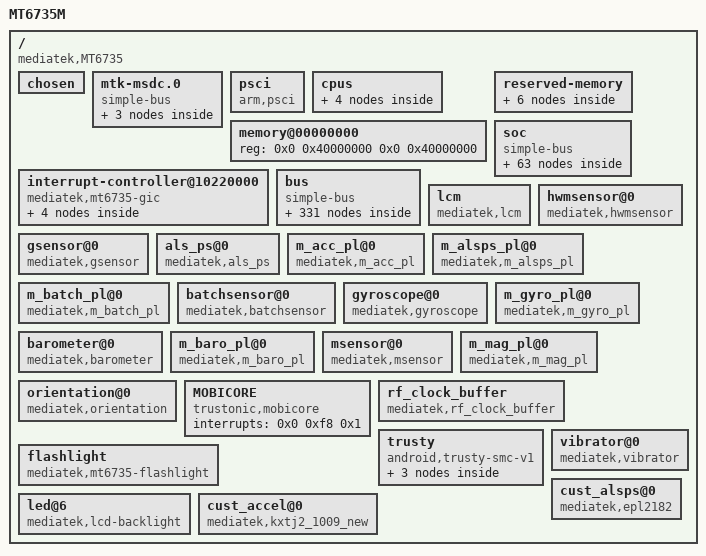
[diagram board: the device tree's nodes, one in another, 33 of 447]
/dts-v1/;

/ {
	model = "MT6735M";
	compatible = "mediatek,MT6735";
	interrupt-parent = <0x1>;
	#address-cells = <0x2>;
	#size-cells = <0x2>;

	chosen {
		bootargs = "console=tty0 console=ttyMT0,921600n1 root=/dev/ram \t\t\tinitrd=0x44000000,0x1000000 loglevel=8 androidboot.hardware=mt6735";
	};

	mtk-msdc.0 {
		compatible = "simple-bus";
		#address-cells = <0x1>;
		#size-cells = <0x1>;
		ranges = <0x0 0x0 0x0 0xffffffff>;

		msdc0@11230000 {
			compatible = "mediatek,mt6735m-mmc";
			reg = <0x11230000 0x10000 0x10000e84 0x2>;
			interrupts = <0x0 0x4f 0x8>;
			status = "okay";
			clk_src = [02];
			bus-width = <0x8>;
			max-frequency = <0xbebc200>;
			cap-mmc-highspeed;
			msdc-sys-suspend;
			mmc-ddr-1_8v;
			mmc-hs200-1_8v;
			mmc-hs400-1_8v;
			non-removable;
			pinctl = <0x2>;
			register_setting = <0x3>;
			host_function = [00];
			bootable;
		};

		msdc1@11240000 {
			compatible = "mediatek,mt6735m-mmc";
			reg = <0x11240000 0x10000 0x10000e84 0x2>;
			interrupts = <0x0 0x50 0x8>;
			status = "okay";
			clk_src = [02];
			bus-width = <0x4>;
			max-frequency = <0xbebc200>;
			msdc-sys-suspend;
			cap-sd-highspeed;
			sd-uhs-sdr12;
			sd-uhs-sdr25;
			sd-uhs-sdr50;
			sd-uhs-sdr104;
			sd-uhs-ddr50;
			pinctl = <0x4>;
			pinctl_sdr104 = <0x5>;
			pinctl_sdr50 = <0x6>;
			pinctl_ddr50 = <0x7>;
			register_setting = <0x8>;
			host_function = [01];
			cd_level = [00];
			cd-gpios = <0x9 0x5 0x0>;
		};

		default {
			compatible = "mediatek, msdc1_ins-eint";
			interrupt-parent = <0xa>;
			interrupts = <0x5 0x8>;
			debounce = <0x5 0x3e8>;
			status = "okay";
		};
	};

	psci {
		compatible = "arm,psci";
		method = "smc";
		cpu_suspend = <0x84000001>;
		cpu_off = <0x84000002>;
		cpu_on = <0x84000003>;
		affinity_info = <0x84000004>;
	};

	cpus {
		#address-cells = <0x1>;
		#size-cells = <0x0>;

		cpu@000 {
			device_type = "cpu";
			compatible = "arm,cortex-a53";
			reg = <0x0>;
			enable-method = "spin-table";
			cpu-release-addr = <0x0 0x40000200>;
			clock-frequency = <0x3b9aca00>;
			linux,phandle = <0xb>;
			phandle = <0xb>;
		};

		cpu@001 {
			device_type = "cpu";
			compatible = "arm,cortex-a53";
			reg = <0x1>;
			enable-method = "spin-table";
			cpu-release-addr = <0x0 0x40000200>;
			clock-frequency = <0x3b9aca00>;
			linux,phandle = <0xc>;
			phandle = <0xc>;
		};

		cpu@002 {
			device_type = "cpu";
			compatible = "arm,cortex-a53";
			reg = <0x2>;
			enable-method = "spin-table";
			cpu-release-addr = <0x0 0x40000200>;
			clock-frequency = <0x3b9aca00>;
			linux,phandle = <0xd>;
			phandle = <0xd>;
		};

		cpu@003 {
			device_type = "cpu";
			compatible = "arm,cortex-a53";
			reg = <0x3>;
			enable-method = "spin-table";
			cpu-release-addr = <0x0 0x40000200>;
			clock-frequency = <0x3b9aca00>;
			linux,phandle = <0xe>;
			phandle = <0xe>;
		};
	};

	memory@00000000 {
		device_type = "memory";
		reg = <0x0 0x40000000 0x0 0x40000000>;
	};

	reserved-memory {
		#address-cells = <0x2>;
		#size-cells = <0x2>;
		ranges;

		atf-reserved-memory@43000000 {
			compatible = "mediatek,mt6735-atf-reserved-memory", "mediatek,mt6735m-atf-reserved-memory", "mediatek,mt6753-atf-reserved-memory";
			no-map;
			reg = <0x0 0x43000000 0x0 0x30000>;
		};

		reserve-memory-ccci_md1 {
			compatible = "mediatek,reserve-memory-ccci_md1";
			no-map;
			size = <0x0 0x3810000>;
			alignment = <0x0 0x2000000>;
			alloc-ranges = <0x0 0x40000000 0x0 0xc0000000>;
		};

		consys-reserve-memory {
			compatible = "mediatek,consys-reserve-memory";
			no-map;
			size = <0x0 0x100000>;
			alignment = <0x0 0x200000>;
		};

		ram_console-reserved-memory@43f00000 {
			compatible = "mediatek,ram_console";
			reg = <0x0 0x43f00000 0x0 0x10000>;
		};

		minirdump-reserved-memory@43ff0000 {
			compatible = "mediatek, minirdump";
			reg = <0x0 0x43ff0000 0x0 0x10000>;
		};

		pstore-reserved-memory@43f10000 {
			compatible = "mediatek,pstore";
			reg = <0x0 0x43f10000 0x0 0xe0000>;
		};
	};

	interrupt-controller@10220000 {
		compatible = "mediatek,mt6735-gic";
		#interrupt-cells = <0x3>;
		#address-cells = <0x0>;
		interrupt-controller;
		reg = <0x0 0x10221000 0x0 0x1000 0x0 0x10222000 0x0 0x1000 0x0 0x10200620 0x0 0x1000>;
		mediatek,wdt_irq = <0xa0>;
		linux,phandle = <0x1>;
		phandle = <0x1>;

		gic-cpuif@0 {
			compatible = "arm,gic-cpuif";
			cpuif-id = <0x0>;
			cpu = <0xb>;
		};

		gic-cpuif@1 {
			compatible = "arm,gic-cpuif";
			cpuif-id = <0x1>;
			cpu = <0xc>;
		};

		gic-cpuif@2 {
			compatible = "arm,gic-cpuif";
			cpuif-id = <0x2>;
			cpu = <0xd>;
		};

		gic-cpuif@3 {
			compatible = "arm,gic-cpuif";
			cpuif-id = <0x3>;
			cpu = <0xe>;
		};
	};

	soc {
		compatible = "simple-bus";
		#address-cells = <0x1>;
		#size-cells = <0x1>;
		ranges;

		cpuxgpt@10200000 {
			compatible = "mediatek,mt6735-cpuxgpt";
			reg = <0x10200000 0x1000>;
			interrupts = <0x0 0x40 0x4 0x0 0x41 0x4 0x0 0x42 0x4 0x0 0x43 0x4 0x0 0x44 0x4 0x0 0x45 0x4 0x0 0x46 0x4 0x0 0x47 0x4>;
		};

		apxgpt@10004000 {
			compatible = "mediatek,mt6735-apxgpt";
			reg = <0x10004000 0x1000>;
			interrupts = <0x0 0x98 0x8>;
			clock-frequency = <0xc65d40>;
		};

		timer {
			compatible = "arm,armv8-timer";
			interrupts = <0x1 0xd 0x8 0x1 0xe 0x8 0x1 0xb 0x8 0x1 0xa 0x8>;
			clock-frequency = <0xc65d40>;
		};

		mt_pmic_regulator {
			compatible = "mediatek,mt_pmic";

			buck_regulators {
				compatible = "mediatek,mt_pmic_buck_regulators";

				buck_vpa {
					regulator-name = "vpa";
					regulator-min-microvolt = <0x7a120>;
					regulator-max-microvolt = <0x37b1d0>;
					regulator-ramp-delay = <0xc350>;
					regulator-enable-ramp-delay = <0xb4>;
				};

				buck_vproc {
					regulator-name = "vproc";
					regulator-min-microvolt = <0x927c0>;
					regulator-max-microvolt = <0x154456>;
					regulator-ramp-delay = <0x186a>;
					regulator-enable-ramp-delay = <0xb4>;
					regulator-always-on;
					regulator-boot-on;
				};

				buck_vcore1 {
					regulator-name = "vcore1";
					regulator-min-microvolt = <0x927c0>;
					regulator-max-microvolt = <0x154456>;
					regulator-ramp-delay = <0x186a>;
					regulator-enable-ramp-delay = <0xb4>;
					regulator-always-on;
					regulator-boot-on;
				};

				buck_vsys22 {
					regulator-name = "vsys22";
					regulator-min-microvolt = <0x124f80>;
					regulator-max-microvolt = <0x1e6c16>;
					regulator-ramp-delay = <0x186a>;
					regulator-enable-ramp-delay = <0xb4>;
					regulator-always-on;
					regulator-boot-on;
				};

				buck_vlte {
					regulator-name = "vlte";
					regulator-min-microvolt = <0x927c0>;
					regulator-max-microvolt = <0x154456>;
					regulator-ramp-delay = <0x186a>;
					regulator-enable-ramp-delay = <0xb4>;
					regulator-always-on;
					regulator-boot-on;
				};
			};

			ldo_regulators {
				compatible = "mediatek,mt_pmic_ldo_regulators";

				ldo_vaux18 {
					regulator-name = "vaux18";
					regulator-min-microvolt = <0x1b7740>;
					regulator-max-microvolt = <0x1b7740>;
					regulator-enable-ramp-delay = <0x108>;
					regulator-boot-on;
					linux,phandle = <0xf>;
					phandle = <0xf>;
				};

				ldo_vtcxo_0 {
					regulator-name = "vtcxo_0";
					regulator-min-microvolt = <0x2ab980>;
					regulator-max-microvolt = <0x2ab980>;
					regulator-enable-ramp-delay = <0x6e>;
					regulator-boot-on;
					linux,phandle = <0x10>;
					phandle = <0x10>;
				};

				ldo_vtcxo_1 {
					regulator-name = "vtcxo_1";
					regulator-min-microvolt = <0x2ab980>;
					regulator-max-microvolt = <0x2ab980>;
					regulator-enable-ramp-delay = <0x6e>;
					linux,phandle = <0x11>;
					phandle = <0x11>;
				};

				ldo_vaud28 {
					regulator-name = "vaud28";
					regulator-min-microvolt = <0x2ab980>;
					regulator-max-microvolt = <0x2ab980>;
					regulator-enable-ramp-delay = <0x108>;
					regulator-boot-on;
					linux,phandle = <0x12>;
					phandle = <0x12>;
				};

				ldo_vcn28 {
					regulator-name = "vcn28";
					regulator-min-microvolt = <0x2ab980>;
					regulator-max-microvolt = <0x2ab980>;
					regulator-enable-ramp-delay = <0x108>;
					linux,phandle = <0x2c>;
					phandle = <0x2c>;
				};

				ldo_vcama {
					regulator-name = "vcama";
					regulator-min-microvolt = <0x16e360>;
					regulator-max-microvolt = <0x2ab980>;
					regulator-enable-ramp-delay = <0x108>;
					regulator-default-on = <0x0>;
					status = "okay";
					linux,phandle = <0x4f>;
					phandle = <0x4f>;
				};

				ldo_vcn33_bt {
					regulator-name = "vcn33_bt";
					regulator-min-microvolt = <0x325aa0>;
					regulator-max-microvolt = <0x36ee80>;
					regulator-enable-ramp-delay = <0x108>;
					linux,phandle = <0x2d>;
					phandle = <0x2d>;
				};

				ldo_vcn33_wifi {
					regulator-name = "vcn33_wifi";
					regulator-min-microvolt = <0x325aa0>;
					regulator-max-microvolt = <0x36ee80>;
					regulator-enable-ramp-delay = <0x108>;
					linux,phandle = <0x2e>;
					phandle = <0x2e>;
				};

				ldo_vusb33 {
					regulator-name = "vusb33";
					regulator-min-microvolt = <0x325aa0>;
					regulator-max-microvolt = <0x325aa0>;
					regulator-enable-ramp-delay = <0x108>;
					regulator-boot-on;
				};

				ldo_vefuse {
					regulator-name = "vefuse";
					regulator-min-microvolt = <0x1b7740>;
					regulator-max-microvolt = <0x2191c0>;
					regulator-enable-ramp-delay = <0x108>;
					linux,phandle = <0x13>;
					phandle = <0x13>;
				};

				ldo_vsim1 {
					regulator-name = "vsim1";
					regulator-min-microvolt = <0x19f0a0>;
					regulator-max-microvolt = <0x200b20>;
					regulator-enable-ramp-delay = <0x108>;
					regulator-default-on = <0x0>;
					status = "okay";
					linux,phandle = <0x14>;
					phandle = <0x14>;
				};

				ldo_vsim2 {
					regulator-name = "vsim2";
					regulator-min-microvolt = <0x19f0a0>;
					regulator-max-microvolt = <0x200b20>;
					regulator-enable-ramp-delay = <0x108>;
					regulator-default-on = <0x0>;
					status = "okay";
					linux,phandle = <0x15>;
					phandle = <0x15>;
				};

				ldo_vemc_3v3 {
					regulator-name = "vemc_3v3";
					regulator-min-microvolt = <0x1b7740>;
					regulator-max-microvolt = <0x325aa0>;
					regulator-enable-ramp-delay = <0x108>;
					regulator-boot-on;
					linux,phandle = <0x16>;
					phandle = <0x16>;
				};

				ldo_vmch {
					regulator-name = "vmch";
					regulator-min-microvolt = <0x2c4020>;
					regulator-max-microvolt = <0x325aa0>;
					regulator-enable-ramp-delay = <0x2c>;
					regulator-boot-on;
					linux,phandle = <0x17>;
					phandle = <0x17>;
				};

				ldo_vtref {
					regulator-name = "vtref";
					regulator-min-microvolt = <0x1b7740>;
					regulator-max-microvolt = <0x1b7740>;
					regulator-enable-ramp-delay = <0xf0>;
					linux,phandle = <0x18>;
					phandle = <0x18>;
				};

				ldo_vmc {
					regulator-name = "vmc";
					regulator-min-microvolt = <0x1b7740>;
					regulator-max-microvolt = <0x325aa0>;
					regulator-enable-ramp-delay = <0x2c>;
					regulator-boot-on;
					linux,phandle = <0x19>;
					phandle = <0x19>;
				};

				ldo_vcamaf {
					regulator-name = "vcamaf";
					regulator-min-microvolt = <0x124f80>;
					regulator-max-microvolt = <0x325aa0>;
					regulator-enable-ramp-delay = <0x108>;
					regulator-default-on = <0x0>;
					status = "okay";
					linux,phandle = <0x51>;
					phandle = <0x51>;
				};

				ldo_vio28 {
					regulator-name = "vio28";
					regulator-min-microvolt = <0x2ab980>;
					regulator-max-microvolt = <0x2ab980>;
					regulator-enable-ramp-delay = <0x108>;
					regulator-boot-on;
					linux,phandle = <0x1a>;
					phandle = <0x1a>;
				};

				ldo_vgp1 {
					regulator-name = "vgp1";
					regulator-min-microvolt = <0x124f80>;
					regulator-max-microvolt = <0x325aa0>;
					regulator-enable-ramp-delay = <0x108>;
					regulator-default-on = <0x0>;
					status = "okay";
					linux,phandle = <0x3e>;
					phandle = <0x3e>;
				};

				ldo_vibr {
					regulator-name = "vibr";
					regulator-min-microvolt = <0x124f80>;
					regulator-max-microvolt = <0x325aa0>;
					regulator-enable-ramp-delay = <0x2c>;
					regulator-default-on = <0x0>;
					status = "okay";
					linux,phandle = <0x1b>;
					phandle = <0x1b>;
				};

				ldo_vcamd {
					regulator-name = "vcamd";
					regulator-min-microvolt = <0xdbba0>;
					regulator-max-microvolt = <0x16e360>;
					regulator-enable-ramp-delay = <0x108>;
					regulator-default-on = <0x0>;
					status = "okay";
					linux,phandle = <0x50>;
					phandle = <0x50>;
				};

				ldo_vrf18_0 {
					regulator-name = "vrf18_0";
					regulator-min-microvolt = <0x1bd8e8>;
					regulator-max-microvolt = <0x1bd8e8>;
					regulator-enable-ramp-delay = <0xdc>;
					linux,phandle = <0x1c>;
					phandle = <0x1c>;
				};

				ldo_vrf18_1 {
					regulator-name = "vrf18_1";
					regulator-min-microvolt = <0x124f80>;
					regulator-max-microvolt = <0x1bd8e8>;
					regulator-enable-ramp-delay = <0xdc>;
					linux,phandle = <0x1d>;
					phandle = <0x1d>;
				};

				ldo_vio18 {
					regulator-name = "vio18";
					regulator-min-microvolt = <0x1b7740>;
					regulator-max-microvolt = <0x1b7740>;
					regulator-enable-ramp-delay = <0x108>;
					regulator-boot-on;
					linux,phandle = <0x1e>;
					phandle = <0x1e>;
				};

				ldo_vcn18 {
					regulator-name = "vcn18";
					regulator-min-microvolt = <0x1b7740>;
					regulator-max-microvolt = <0x1b7740>;
					regulator-enable-ramp-delay = <0x2c>;
					linux,phandle = <0x2b>;
					phandle = <0x2b>;
				};

				ldo_vcamio {
					regulator-name = "vcamio";
					regulator-min-microvolt = <0x124f80>;
					regulator-max-microvolt = <0x1b7740>;
					regulator-enable-ramp-delay = <0xdc>;
					regulator-default-on = <0x0>;
					status = "okay";
					linux,phandle = <0x52>;
					phandle = <0x52>;
				};

				ldo_vsram {
					regulator-name = "vsram";
					regulator-min-microvolt = <0xaae60>;
					regulator-max-microvolt = <0x16caf6>;
					regulator-enable-ramp-delay = <0xdc>;
					regulator-ramp-delay = <0x186a>;
					regulator-boot-on;
					linux,phandle = <0x1f>;
					phandle = <0x1f>;
				};

				ldo_vm {
					regulator-name = "vm";
					regulator-min-microvolt = <0x12ebc0>;
					regulator-max-microvolt = <0x177fa0>;
					regulator-enable-ramp-delay = <0x108>;
					regulator-boot-on;
					linux,phandle = <0x20>;
					phandle = <0x20>;
				};
			};

			regulators_supply {
				compatible = "mediatek,mt_pmic_regulator_supply";
				vaux18-supply = <0xf>;
				vtcxo_0-supply = <0x10>;
				vtcxo_1-supply = <0x11>;
				vaud28-supply = <0x12>;
				vefuse-supply = <0x13>;
				vsim1-supply = <0x14>;
				vsim2-supply = <0x15>;
				vemc_3v3-supply = <0x16>;
				vmch-supply = <0x17>;
				vtref-supply = <0x18>;
				vmc-supply = <0x19>;
				vio28-supply = <0x1a>;
				vibr-supply = <0x1b>;
				vrf18_0-supply = <0x1c>;
				vrf18_1-supply = <0x1d>;
				vio18-supply = <0x1e>;
				vsram-supply = <0x1f>;
				vm-supply = <0x20>;
			};
		};

		toprgu@10212000 {
			compatible = "mediatek,mt6735-rgu";
			reg = <0x10212000 0x1000>;
			interrupts = <0x0 0x80 0x2>;
		};

		mcu_biu@10300000 {
			compatible = "mediatek,mt6735-mcu_biu";
			reg = <0x10300000 0x8000>;
		};

		gpio {
			compatible = "mediatek,gpio_usage_mapping";
			GPIO_SIM1_HOT_PLUG = <0x8>;
			GPIO_SIM2_HOT_PLUG = <0x9>;
			GPIO_CMDAT1 = <0x2b>;
			GPIO_SIM2_SCLK = <0xa0>;
			GPIO_SIM2_SRST = <0xa1>;
			GPIO_SIM2_SIO = <0xa2>;
			GPIO_SIM1_SCLK = <0xa3>;
			GPIO_SIM1_SRST = <0xa4>;
			GPIO_SIM1_SIO = <0xa5>;
		};

		gpio@10211000 {
			compatible = "mediatek,gpio";
			reg = <0x10211000 0x1000>;
		};

		dramc_nao@1020e000 {
			compatible = "mediatek,mt6735-dramc_nao";
			reg = <0x1020e000 0x1000>;
		};

		ddrphy@10213000 {
			compatible = "mediatek,mt6735-ddrphy";
			reg = <0x10213000 0x1000>;
		};

		dramc@10214000 {
			compatible = "mediatek,mt6735-dramc";
			reg = <0x10214000 0x1000>;
			clock-names = "infra-cqdma";
		};

		keypad@10003000 {
			compatible = "mediatek,mt6735-keypad", "mediatek,mt6735m-keypad";
			reg = <0x10003000 0x1000>;
			interrupts = <0x0 0xa4 0x2>;
			mediatek,kpd-key-debounce = <0x400>;
			mediatek,kpd-sw-pwrkey = <0x74>;
			mediatek,kpd-hw-pwrkey = <0x8>;
			mediatek,kpd-sw-rstkey = <0x73>;
			mediatek,kpd-hw-rstkey = <0x11>;
			mediatek,kpd-use-extend-type = <0x0>;
			mediatek,kpd-hw-map-num = <0x48>;
			mediatek,kpd-hw-init-map = <0x73 0x72 0x0 0x0 0x0 0x0 0x0 0x0 0x0 0x0 0x0 0x0 0x0 0x0 0x0 0x0 0x0 0x0 0x0 0x0 0x0 0x0 0x0 0x0 0x0 0x0 0x0 0x0 0x0 0x0 0x0 0x0 0x0 0x0 0x0 0x0 0x0 0x0 0x0 0x0 0x0 0x0 0x0 0x0 0x0 0x0 0x0 0x0 0x0 0x0 0x0 0x0 0x0 0x0 0x0 0x0 0x0 0x0 0x0 0x0 0x0 0x0 0x0 0x0 0x0 0x0 0x0 0x0 0x0 0x0 0x0 0x0>;
			mediatek,kpd-pwrkey-eint-gpio = <0x0>;
			mediatek,kpd-pwkey-gpio-din = <0x0>;
			mediatek,kpd-hw-dl-key0 = <0x0>;
			mediatek,kpd-hw-dl-key1 = <0x1>;
			mediatek,kpd-hw-dl-key2 = <0x8>;
			mediatek,kpd-hw-recovery-key = <0x11>;
			mediatek,kpd-hw-factory-key = <0x1>;
			status = "okay";
		};

		irtx@11011000 {
			compatible = "mediatek,irtx";
			reg = <0x11011000 0x1000>;
			interrupts = <0x0 0x7c 0x4>;
			pwm_ch = <0x0>;
		};

		apuart0@11002000 {
			cell-index = <0x0>;
			compatible = "mediatek,mt6735-uart";
			reg = <0x11002000 0x1000 0x11000380 0x1000 0x11000400 0x80>;
			interrupts = <0x0 0x5b 0x8 0x0 0x67 0x8 0x0 0x68 0x8>;
		};

		apuart1@11003000 {
			cell-index = <0x1>;
			compatible = "mediatek,mt6735-uart";
			reg = <0x11003000 0x1000 0x11000480 0x80 0x11000500 0x80>;
			interrupts = <0x0 0x5c 0x8 0x0 0x69 0x8 0x0 0x6a 0x8>;
		};

		apuart2@11004000 {
			cell-index = <0x2>;
			compatible = "mediatek,mt6735-uart";
			reg = <0x11004000 0x1000 0x11000580 0x80 0x11000600 0x80>;
			interrupts = <0x0 0x5d 0x8 0x0 0x6b 0x8 0x0 0x6c 0x8>;
			pinctrl-names = "uart2_gpio_default", "uart2_rx_set", "uart2_rx_clear", "uart2_tx_set", "uart2_tx_clear";
			pinctrl-0 = <0x21>;
			pinctrl-1 = <0x22>;
			pinctrl-2 = <0x23>;
			pinctrl-3 = <0x24>;
			pinctrl-4 = <0x25>;
		};

		apuart3@11005000 {
			cell-index = <0x3>;
			compatible = "mediatek,mt6735-uart";
			reg = <0x11005000 0x1000 0x11000680 0x80 0x11000700 0x80>;
			interrupts = <0x0 0x5e 0x8 0x0 0x6d 0x8 0x0 0x6e 0x8>;
			pinctrl-names = "uart3_gpio_default", "uart3_rx_set", "uart3_rx_clear", "uart3_tx_set", "uart3_tx_clear";
			pinctrl-0 = <0x26>;
			pinctrl-1 = <0x27>;
			pinctrl-2 = <0x28>;
			pinctrl-3 = <0x29>;
			pinctrl-4 = <0x2a>;
		};

		spi@1100a000 {
			compatible = "mediatek,mt6735m-spi";
			cell-index = <0x0>;
			spi-padmacro = <0x0>;
			reg = <0x1100a000 0x1000>;
			interrupts = <0x0 0x76 0x8>;
		};

		btif_tx@11000780 {
			compatible = "mediatek,btif_tx";
			reg = <0x11000780 0x80>;
			interrupts = <0x0 0x6f 0x8>;
		};

		btif_rx@11000800 {
			compatible = "mediatek,btif_rx";
			reg = <0x11000800 0x80>;
			interrupts = <0x0 0x70 0x8>;
		};

		btif@1100c000 {
			compatible = "mediatek,btif";
			reg = <0x1100c000 0x1000>;
			interrupts = <0x0 0x5a 0x8>;
		};

		consys@18070000 {
			compatible = "mediatek,mt6735m-consys", "mediatek,mt6735-consys";
			reg = <0x18070000 0x200 0x10212000 0x100 0x10000000 0x2000 0x10006000 0x1000>;
			interrupts = <0x0 0xe3 0x8 0x0 0xe1 0x8>;
			vcn18-supply = <0x2b>;
			vcn28-supply = <0x2c>;
			vcn33_bt-supply = <0x2d>;
			vcn33_wifi-supply = <0x2e>;
			pinctrl-names = "default", "gps_lna_state_init", "gps_lna_state_oh", "gps_lna_state_ol";
			pinctrl-0 = <0x2f>;
			pinctrl-1 = <0x30>;
			pinctrl-2 = <0x31>;
			pinctrl-3 = <0x32>;
			status = "okay";
		};

		hacc@10008000 {
			compatible = "mediatek,hacc";
			reg = <0x10008000 0x1000>;
			interrupts = <0x0 0xae 0x8>;
		};

		als {
			compatible = "mediatek, als-eint";
			interrupt-parent = <0xa>;
			interrupts = <0x2 0x8>;
			debounce = <0x2 0x0>;
			status = "okay";
		};

		gse_1 {
			compatible = "mediatek, gse_1-eint";
			status = "disabled";
		};

		ext_buck_oc {
			compatible = "mediatek, ext_buck_oc-eint";
			status = "okay";
			interrupt-parent = <0xa>;
			interrupts = <0x4e 0x4>;
			debounce = <0x4e 0x0>;
		};

		dsi_te {
			compatible = "mediatek, dsi_te_1-eint";
			status = "disabled";
		};
	};

	bus {
		compatible = "simple-bus";
		#address-cells = <0x1>;
		#size-cells = <0x1>;
		ranges = <0x0 0x0 0x0 0xffffffff>;

		INFRACFG_AO@0x10000000 {
			compatible = "mediatek,INFRACFG_AO";
			reg = <0x10000000 0x1000>;
		};

		PWRAP@0x10001000 {
			compatible = "mediatek,PWRAP";
			reg = <0x10001000 0x1000>;
			interrupts = <0x0 0xa3 0x4>;
		};

		PERICFG@0x10002000 {
			compatible = "mediatek,PERICFG";
			reg = <0x10002000 0x1000>;
		};

		FHCTL@0x10209F00 {
			compatible = "mediatek,FHCTL";
			reg = <0x10209f00 0x100>;
		};

		KP@0x10003000 {
			compatible = "mediatek,KP";
			reg = <0x10003000 0x1000>;
			interrupts = <0x0 0xa4 0x2>;
		};

		eintc@10005000 {
			compatible = "mediatek,mt-eic";
			reg = <0x10005000 0x1000>;
			interrupts = <0x0 0x99 0x4>;
			#interrupt-cells = <0x2>;
			interrupt-controller;
			mediatek,max_eint_num = <0xd5>;
			mediatek,mapping_table_entry = <0x0>;
			linux,phandle = <0xa>;
			phandle = <0xa>;

			MD1_SIM1_HOT_PLUG_EINT@0 {
				compatible = "mediatek,MD1_SIM1_HOT_PLUG_EINT-eint";
				interrupts = <0x0 0x4>;
				debounce = <0x0 0x186a0>;
				dedicated = <0x0 0x0>;
				src_pin = <0x0 0x1>;
				sockettype = <0x0 0x0>;
				status = "okay";
			};

			MD1_SIM2_HOT_PLUG_EINT@1 {
				compatible = "mediatek,MD1_SIM2_HOT_PLUG_EINT-eint";
				interrupts = <0x1 0x4>;
				debounce = <0x1 0x186a0>;
				dedicated = <0x1 0x0>;
				src_pin = <0x1 0x2>;
				sockettype = <0x1 0x0>;
				status = "okay";
			};

			pmic@206 {
				compatible = "mediatek, pmic-eint";
				interrupt-parent = <0xa>;
				interrupts = <0xce 0x4>;
				debounce = <0xce 0x3e8>;
			};
		};

		SLEEP@0x10006000 {
			compatible = "mediatek,SLEEP";
			reg = <0x10006000 0x1000>;
			interrupts = <0x0 0xa5 0x8 0x0 0xa6 0x8 0x0 0xa7 0x8 0x0 0xa8 0x8>;
		};

		DEVAPC_AO@10007000 {
			compatible = "mediatek,DEVAPC_AO";
			reg = <0x10007000 0x1000>;
		};

		RSVD@0x10009000 {
			compatible = "mediatek,RSVD";
			reg = <0x10009000 0x1000>;
		};

		bat_meter {
			compatible = "mediatek,bat_meter";
		};

		bat_notify {
			compatible = "mediatek,bat_notify";
		};

		bat_comm {
			compatible = "mediatek,battery";
		};

		mdcldma@1000A000 {
			compatible = "mediatek,mdcldma";
			reg = <0x1000a000 0x1000 0x1000b000 0x1000 0x1021a000 0x1000 0x1021b000 0x1000 0x1020a000 0x1000 0x1020b000 0x1000>;
			interrupts = <0x0 0x91 0x4 0x0 0x8c 0x8 0x0 0xdd 0x2>;
			mediatek,md_id = <0x0>;
			mediatek,cldma_capability = <0x2>;
			mediatek,md_smem_size = <0x10000>;
			pinctrl-names = "default", "vsram_output_low", "vsram_output_high", "RFIC0_01_mode", "RFIC0_04_mode";
			pinctrl-0 = <0x33>;
			pinctrl-1 = <0x34>;
			pinctrl-2 = <0x35>;
			pinctrl-3 = <0x36>;
			pinctrl-4 = <0x37>;
		};

		dbgapb_base@1011A000 {
			compatible = "mediatek,dbgapb_base";
			reg = <0x1011a000 0x100>;
		};

		simswitch@0 {
			compatible = "mediatek,sim_switch";
			pinctrl-names = "default", "hot_plug_mode1", "hot_plug_mode2", "two_sims_bound_to_md1", "sim1_md3_sim2_md1";
			pinctrl-0 = <0x38>;
			pinctrl-1 = <0x39>;
			pinctrl-2 = <0x3a>;
			pinctrl-3 = <0x3b>;
			pinctrl-4 = <0x3c>;
		};

		DNL3_XGPT64@0x1000C000 {
			compatible = "mediatek,DNL3_XGPT64";
			reg = <0x1000c000 0x1000>;
			interrupts = <0x0 0x9f 0x8>;
		};

		MCUCFG@0x10200000 {
			compatible = "mediatek,MCUCFG";
			reg = <0x10200000 0x200>;
			interrupts = <0x0 0x0 0x8>;
		};

		mcucfg@10200000 {
			compatible = "mediatek,mt6735-mcucfg";
			reg = <0x10200000 0x200>;
			interrupts = <0x0 0x47 0x4>;
		};

		RSVD@0x10200200 {
			compatible = "mediatek,RSVD";
			reg = <0x10200200 0x200>;
		};

		MCUSYS_MISCCFG@0x10200400 {
			compatible = "mediatek,MCUSYS_MISCCFG";
			reg = <0x10200400 0x200>;
		};

		MCUSYS_MCUCFG@0x10200600 {
			compatible = "mediatek,MCUSYS_MCUCFG";
			reg = <0x10200600 0xa00>;
		};

		INFRACFG@0x10201000 {
			compatible = "mediatek,INFRACFG";
			reg = <0x10201000 0x1000>;
		};

		SRAMROM@0x10202000 {
			compatible = "mediatek,SRAMROM";
			reg = <0x10202000 0x1000>;
		};

		EMI@0x10203000 {
			compatible = "mediatek,EMI";
			reg = <0x10203000 0x1000>;
			interrupts = <0x0 0x88 0x4>;
		};

		sys_cirq@10204000 {
			compatible = "mediatek,mt6735-sys_cirq";
			reg = <0x10204000 0x1000>;
			interrupts = <0x0 0xe7 0x8>;
			mediatek,cirq_num = <0x9f>;
			mediatek,spi_start_offset = <0x48>;
		};

		m4u@10205000 {
			cell-index = <0x0>;
			compatible = "mediatek,m4u";
			reg = <0x10205000 0x1000>;
			interrupts = <0x0 0x92 0x8>;
		};

		EFUSEC@10206000 {
			compatible = "mediatek,EFUSEC";
			reg = <0x10206000 0x1000>;
		};

		DEVAPC@10207000 {
			compatible = "mediatek,DEVAPC";
			reg = <0x10207000 0x1000>;
			interrupts = <0x0 0x86 0x8>;
		};

		bus_dbg@10208000 {
			compatible = "mediatek,bus_dbg-v1";
			reg = <0x10208000 0x1000>;
			interrupts = <0x0 0x89 0x8>;
		};

		APMIXED@0x10209000 {
			compatible = "mediatek,APMIXED";
			reg = <0x10209000 0x1000>;
		};

		RSVD@0x1020C000 {
			compatible = "mediatek,RSVD";
			reg = <0x1020c000 0x1000>;
		};

		INFRA_MBIST@0x1020D000 {
			compatible = "mediatek,INFRA_MBIST";
			reg = <0x1020d000 0x1000>;
		};

		TRNG@0x1020F000 {
			compatible = "mediatek,TRNG";
			reg = <0x1020f000 0x1000>;
			interrupts = <0x0 0x8d 0x8>;
		};

		CKSYS@0x10210000 {
			compatible = "mediatek,CKSYS";
			reg = <0x10210000 0x1000>;
		};

		MIPI_RX_ANA_CSI0@0x10215800 {
			compatible = "mediatek,MIPI_RX_ANA_CSI0";
			reg = <0x10215800 0x400>;
		};

		MIPI_RX_ANA_CSI1@0x10215C00 {
			compatible = "mediatek,MIPI_RX_ANA_CSI1";
			reg = <0x10215c00 0x400>;
		};

		gcpu@10216000 {
			compatible = "mediatek,gcpu";
			reg = <0x10216000 0x1000>;
			interrupts = <0x0 0x96 0x8>;
		};

		gce@10217000 {
			compatible = "mediatek,gce";
			reg = <0x10217000 0xc00>;
			interrupts = <0x0 0x97 0x8 0x0 0x94 0x8>;
			disp_mutex_reg = <0x14015000 0x1000>;
			g3d_config_base = <0x13000000 0x0 0xffff0000>;
			mmsys_config_base = <0x14000000 0x1 0xffff0000>;
			disp_dither_base = <0x14010000 0x2 0xffff0000>;
			mm_na_base = <0x14020000 0x3 0xffff0000>;
			imgsys_base = <0x15000000 0x4 0xffff0000>;
			vdec_gcon_base = <0x16000000 0x5 0xffff0000>;
			venc_gcon_base = <0x17000000 0x6 0xffff0000>;
			conn_peri_base = <0x18000000 0x7 0xffff0000>;
			topckgen_base = <0x10000000 0x8 0xffff0000>;
			kp_base = <0x10010000 0x9 0xffff0000>;
			scp_sram_base = <0x10020000 0xa 0xffff0000>;
			infra_na3_base = <0x10030000 0xb 0xffff0000>;
			infra_na4_base = <0x10040000 0xc 0xffff0000>;
			scp_base = <0x10050000 0xd 0xffff0000>;
			mcucfg_base = <0x10200000 0xe 0xffff0000>;
			gcpu_base = <0x10210000 0xf 0xffff0000>;
			usb0_base = <0x11200000 0x10 0xffff0000>;
			usb_sif_base = <0x11210000 0x11 0xffff0000>;
			audio_base = <0x11220000 0x12 0xffff0000>;
			msdc0_base = <0x11230000 0x13 0xffff0000>;
			msdc1_base = <0x11240000 0x14 0xffff0000>;
			msdc2_base = <0x11250000 0x15 0xffff0000>;
			msdc3_base = <0x11260000 0x16 0xffff0000>;
			pwm_sw_base = <0x1100e000 0x63 0xfffff000>;
			mdp_rdma0_sof = <0x0>;
			mdp_rsz0_sof = <0x1>;
			mdp_rsz1_sof = <0x2>;
			mdp_tdshp_sof = <0x3>;
			mdp_wdma_sof = <0x4>;
			mdp_wrot_sof = <0x5>;
			disp_ovl0_sof = <0x6>;
			disp_rdma0_sof = <0x8>;
			disp_rdma1_sof = <0x9>;
			disp_wdma0_sof = <0xa>;
			disp_ccorr_sof = <0xb>;
			disp_color_sof = <0xc>;
			disp_aal_sof = <0xd>;
			disp_gamma_sof = <0xe>;
			disp_dither_sof = <0xf>;
			disp_pwm0_sof = <0x11>;
			mdp_rdma0_frame_done = <0x12>;
			mdp_rsz0_frame_done = <0x13>;
			mdp_rsz1_frame_done = <0x14>;
			mdp_tdshp_frame_done = <0x15>;
			mdp_wdma_frame_done = <0x16>;
			mdp_wrot_write_frame_done = <0x17>;
			mdp_wrot_read_frame_done = <0x18>;
			disp_ovl0_frame_done = <0x19>;
			disp_rdma0_frame_done = <0x1b>;
			disp_rdma1_frame_done = <0x1c>;
			disp_wdma0_frame_done = <0x1d>;
			disp_ccorr_frame_done = <0x1e>;
			disp_color_frame_done = <0x1f>;
			disp_aal_frame_done = <0x20>;
			disp_gamma_frame_done = <0x21>;
			disp_dither_frame_done = <0x22>;
			disp_dpi0_frame_done = <0x24>;
			disp_dsi0_frame_done = <0x25>;
			stream_done_0 = <0x26>;
			stream_done_1 = <0x27>;
			stream_done_2 = <0x28>;
			stream_done_3 = <0x29>;
			stream_done_4 = <0x2a>;
			stream_done_5 = <0x2b>;
			stream_done_6 = <0x2c>;
			stream_done_7 = <0x2d>;
			stream_done_8 = <0x2e>;
			stream_done_9 = <0x2f>;
			buf_underrun_event_0 = <0x30>;
			buf_underrun_event_1 = <0x31>;
			dsi0_te_event = <0x32>;
			isp_frame_done_p2_1 = <0x42>;
			isp_frame_done_p2_0 = <0x43>;
			seninf_cam0_fifo_full = <0x49>;
			apxgpt2_count = <0x10004028>;
		};

		smi_larb0@14016000 {
			compatible = "mediatek,smi_larb0";
			reg = <0x14016000 0x1000>;
			interrupts = <0x0 0xb0 0x8>;
		};

		smi_larb2@15001000 {
			compatible = "mediatek,smi_larb2";
			reg = <0x15001000 0x1000>;
			interrupts = <0x0 0xb2 0x8>;
		};

		smi_common@14017000 {
			compatible = "mediatek,smi_common";
			reg = <0x14017000 0x1000 0x14016000 0x1000 0x16010000 0x1000 0x15001000 0x1000>;
		};

		smi_larb1@16010000 {
			compatible = "mediatek,smi_larb1";
			reg = <0x16010000 0x10000>;
			interrupts = <0x0 0xb1 0x8>;
		};

		cqdma@10217c00 {
			compatible = "mediatek,cqdma";
			reg = <0x10217c00 0x400>;
			interrupts = <0x0 0x8a 0x8>;
			nr_channel = <0x1>;
		};

		AP_CCIF1@0x10218000 {
			compatible = "mediatek,AP_CCIF1";
			reg = <0x10218000 0x1000>;
			interrupts = <0x0 0x8b 0x4>;
		};

		MD_CCIF1@0x10219000 {
			compatible = "mediatek,MD_CCIF1";
			reg = <0x10219000 0x1000>;
		};

		INFRA_MD@0x1021C000 {
			compatible = "mediatek,INFRA_MD";
			reg = <0x1021c000 0x1000>;
		};

		DBGAPB@0x10400000 {
			compatible = "mediatek,DBGAPB";
			reg = <0x10400000 0xc00000>;
			interrupts = <0x0 0x84 0x8>;
		};

		DEBUGTOP_CA7L@0x10800000 {
			compatible = "mediatek,DEBUGTOP_CA7L";
			reg = <0x10800000 0x400000>;
		};

		DEBUGTOP_MD1@0x10450000 {
			compatible = "mediatek,DEBUGTOP_MD1";
			reg = <0x10450000 0x20000>;
		};

		DEBUGTOP_MD2@0x10470000 {
			compatible = "mediatek,DEBUGTOP_MD2";
			reg = <0x10470000 0x10000>;
		};

		CA9@0x10220000 {
			compatible = "mediatek,CA9";
			reg = <0x10220000 0x8000>;
		};

		cpu_dbgapb {
			compatible = "mediatek,mt6735-dbg_debug";
			num = <0x4>;
			reg = <0x10810000 0x1000 0x10910000 0x1000 0x10a10000 0x1000 0x10b10000 0x1000>;
		};

		dma@11000000 {
			compatible = "mediatek,ap_dma";
			reg = <0x11000000 0x1000>;
			interrupts = <0x0 0x61 0x8>;
		};

		AP_DMA_IRDA@0x11000100 {
			compatible = "mediatek,AP_DMA_IRDA";
			reg = <0x11000100 0x80>;
			interrupts = <0x0 0x62 0x8>;
		};

		adc_hw@11001000 {
			compatible = "mediatek,mt6735-auxadc";
			reg = <0x11001000 0x1000>;
			interrupts = <0x0 0x4c 0x2>;

			adc_channel@ {
				compatible = "mediatek,adc_channel";
				mediatek,temperature0 = <0x0>;
				mediatek,temperature1 = <0x1>;
				mediatek,adc_fdd_rf_params_dynamic_custom_ch = <0xc>;
				status = "okay";
			};
		};

		PWM@0x11006000 {
			compatible = "mediatek,PWM";
			reg = <0x11006000 0x1000>;
			interrupts = <0x0 0x4d 0x8>;
		};

		G3D_CONFIG@0x13000000 {
			compatible = "mediatek,G3D_CONFIG";
			reg = <0x13000000 0x1000>;
		};

		IMGSYS@0x15000000 {
			compatible = "mediatek,IMGSYS";
			reg = <0x15000000 0x1000>;
		};

		syscfg_pctl_a@0x10211000 {
			compatible = "mediatek,mt6735-pctl-a-syscfg", "syscon";
			reg = <0x10211000 0x1000>;
			linux,phandle = <0x3d>;
			phandle = <0x3d>;
		};

		pinctrl@0x10211000 {
			compatible = "mediatek,mt6735-pinctrl";
			reg = <0x10211000 0x1000>;
			mediatek,pctl-regmap = <0x3d>;
			pins-are-numbered;
			gpio-controller;
			#gpio-cells = <0x2>;
			linux,phandle = <0x9>;
			phandle = <0x9>;

			uart0gpiodefault {
			};

			uart0_rx_set@gpio74 {

				pins_cmd_dat {
					pins = <0x4a01>;
				};
			};

			uart0_rx_clear@gpio74 {

				pins_cmd_dat {
					pins = <0x4a00>;
					slew-rate = <0x1>;
					output-high;
				};
			};

			uart0_tx_set@gpio75 {

				pins_cmd_dat {
					pins = <0x4b01>;
				};
			};

			uart0_tx_clear@gpio75 {

				pins_cmd_dat {
					pins = <0x4b00>;
					slew-rate = <0x1>;
					output-high;
				};
			};

			uart1gpiodefault {
			};

			uart1_rx_set@gpio76 {

				pins_cmd_dat {
					pins = <0x4c01>;
				};
			};

			uart1_rx_clear@gpio76 {

				pins_cmd_dat {
					pins = <0x4c00>;
					slew-rate = <0x1>;
					output-high;
				};
			};

			uart1_tx_set@gpio77 {

				pins_cmd_dat {
					pins = <0x4d01>;
				};
			};

			uart1_tx_clear@gpio77 {

				pins_cmd_dat {
					pins = <0x4d00>;
					slew-rate = <0x1>;
					output-high;
				};
			};

			uart2gpiodefault {
				linux,phandle = <0x21>;
				phandle = <0x21>;
			};

			uart2_rx_set@gpio57 {
				linux,phandle = <0x22>;
				phandle = <0x22>;

				pins_cmd_dat {
					pins = <0x3901>;
				};
			};

			uart2_rx_clear@gpio57 {
				linux,phandle = <0x23>;
				phandle = <0x23>;

				pins_cmd_dat {
					pins = <0x3900>;
					slew-rate = <0x1>;
					output-high;
				};
			};

			uart2_tx_set@gpio58 {
				linux,phandle = <0x24>;
				phandle = <0x24>;

				pins_cmd_dat {
					pins = <0x3a01>;
				};
			};

			uart2_tx_clear@gpio58 {
				linux,phandle = <0x25>;
				phandle = <0x25>;

				pins_cmd_dat {
					pins = <0x3a00>;
					slew-rate = <0x1>;
					output-high;
				};
			};

			uart3gpiodefault {
				linux,phandle = <0x26>;
				phandle = <0x26>;
			};

			uart3_rx_set@gpio59 {
				linux,phandle = <0x27>;
				phandle = <0x27>;

				pins_cmd_dat {
					pins = <0x3b01>;
				};
			};

			uart3_rx_clear@gpio59 {
				linux,phandle = <0x28>;
				phandle = <0x28>;

				pins_cmd_dat {
					pins = <0x3b00>;
					slew-rate = <0x1>;
					output-high;
				};
			};

			uart3_tx_set@gpio60 {
				linux,phandle = <0x29>;
				phandle = <0x29>;

				pins_cmd_dat {
					pins = <0x3c01>;
				};
			};

			uart3_tx_clear@gpio60 {
				linux,phandle = <0x2a>;
				phandle = <0x2a>;

				pins_cmd_dat {
					pins = <0x3c00>;
					slew-rate = <0x1>;
					output-high;
				};
			};

			ssw0default {
				linux,phandle = <0x38>;
				phandle = <0x38>;
			};

			ssw@1 {
				linux,phandle = <0x39>;
				phandle = <0x39>;

				pins_cmd0_dat {
					pins = <0x800>;
					bias-disable;
				};

				pins_cmd1_dat {
					pins = <0x900>;
					bias-disable;
				};
			};

			ssw@2 {
				linux,phandle = <0x3a>;
				phandle = <0x3a>;

				pins_cmd0_dat {
					pins = <0x800>;
					bias-disable;
				};

				pins_cmd1_dat {
					pins = <0x900>;
					bias-disable;
				};
			};

			ssw@3 {
				linux,phandle = <0x3b>;
				phandle = <0x3b>;

				pins_cmd0_dat {
					pins = <0xa301>;
					slew-rate = <0x1>;
				};

				pins_cmd1_dat {
					pins = <0xa401>;
					slew-rate = <0x1>;
				};

				pins_cmd2_dat {
					pins = <0xa501>;
					slew-rate = <0x0>;
					bias-pull-up = <0x0>;
				};

				pins_cmd3_dat {
					pins = <0xa001>;
					slew-rate = <0x1>;
				};

				pins_cmd4_dat {
					pins = <0xa101>;
					slew-rate = <0x1>;
				};

				pins_cmd5_dat {
					pins = <0xa201>;
					slew-rate = <0x0>;
					bias-pull-up = <0x0>;
				};
			};

			ssw@4 {
				linux,phandle = <0x3c>;
				phandle = <0x3c>;

				pins_cmd0_dat {
					pins = <0xa304>;
				};

				pins_cmd1_dat {
					pins = <0xa404>;
				};

				pins_cmd2_dat {
					pins = <0xa504>;
				};

				pins_cmd3_dat {
					pins = <0xa001>;
				};

				pins_cmd4_dat {
					pins = <0xa101>;
				};

				pins_cmd5_dat {
					pins = <0xa201>;
				};
			};

			vsram0default {
				linux,phandle = <0x33>;
				phandle = <0x33>;
			};

			vsram@1 {
				linux,phandle = <0x34>;
				phandle = <0x34>;

				pins_cmd_dat {
					pins = <0x8c00>;
					slew-rate = <0x1>;
					output-low;
				};
			};

			vsram@2 {
				linux,phandle = <0x35>;
				phandle = <0x35>;

				pins_cmd_dat {
					pins = <0x8c00>;
					slew-rate = <0x1>;
					output-high;
				};
			};

			clockbuf@1 {
				linux,phandle = <0x36>;
				phandle = <0x36>;

				pins_cmd0_dat {
					pins = <0x6e01>;
				};

				pins_cmd1_dat {
					pins = <0x6f01>;
				};

				pins_cmd2_dat {
					pins = <0x7001>;
				};

				pins_cmd3_dat {
					pins = <0x7101>;
				};

				pins_cmd4_dat {
					pins = <0x7201>;
				};
			};

			clockbuf@2 {
				linux,phandle = <0x37>;
				phandle = <0x37>;

				pins_cmd0_dat {
					pins = <0x6e04>;
				};

				pins_cmd1_dat {
					pins = <0x6f04>;
				};

				pins_cmd2_dat {
					pins = <0x7004>;
				};

				pins_cmd3_dat {
					pins = <0x7104>;
				};

				pins_cmd4_dat {
					pins = <0x7204>;
				};
			};

			alspspincfg {
				linux,phandle = <0x5f>;
				phandle = <0x5f>;

				pins_cmd_dat {
					pins = <0x200>;
					slew-rate = <0x0>;
					bias-pull-up = <0x0>;
				};
			};

			alspsdefaultcfg {
				linux,phandle = <0x5e>;
				phandle = <0x5e>;
			};

			acc_eint0default {
				linux,phandle = <0x45>;
				phandle = <0x45>;
			};

			acc_eint@0 {
				linux,phandle = <0x46>;
				phandle = <0x46>;

				pins_cmd_dat {
					pins = <0x600>;
					slew-rate = <0x0>;
					bias-disable;
				};
			};

			eint0default {
				linux,phandle = <0x3f>;
				phandle = <0x3f>;
			};

			eint@0 {
				linux,phandle = <0x40>;
				phandle = <0x40>;

				pins_cmd_dat {
					pins = <0xa00>;
					slew-rate = <0x0>;
					bias-disable;
				};
			};

			eintoutput0 {
				linux,phandle = <0x41>;
				phandle = <0x41>;

				pins_cmd_dat {
					pins = <0xa00>;
					slew-rate = <0x1>;
					output-low;
				};
			};

			eintoutput1 {
				linux,phandle = <0x42>;
				phandle = <0x42>;

				pins_cmd_dat {
					pins = <0xa00>;
					slew-rate = <0x1>;
					output-high;
				};
			};

			rstoutput0 {
				linux,phandle = <0x43>;
				phandle = <0x43>;

				pins_cmd_dat {
					pins = <0x3e00>;
					slew-rate = <0x1>;
					output-low;
				};
			};

			rstoutput1 {
				linux,phandle = <0x44>;
				phandle = <0x44>;

				pins_cmd_dat {
					pins = <0x3e00>;
					slew-rate = <0x1>;
					output-high;
				};
			};

			cam0@0 {
				linux,phandle = <0x54>;
				phandle = <0x54>;

				pins_cmd_dat {
					pins = <0x2c00>;
					slew-rate = <0x1>;
					output-low;
				};
			};

			cam0@1 {
				linux,phandle = <0x55>;
				phandle = <0x55>;

				pins_cmd_dat {
					pins = <0x2c00>;
					slew-rate = <0x1>;
					output-high;
				};
			};

			cam0@2 {
				linux,phandle = <0x56>;
				phandle = <0x56>;

				pins_cmd_dat {
					pins = <0x700>;
					slew-rate = <0x1>;
					output-low;
				};
			};

			cam0@3 {
				linux,phandle = <0x57>;
				phandle = <0x57>;

				pins_cmd_dat {
					pins = <0x700>;
					slew-rate = <0x1>;
					output-high;
				};
			};

			cam1@0 {
				linux,phandle = <0x58>;
				phandle = <0x58>;

				pins_cmd_dat {
					pins = <0xb00>;
					slew-rate = <0x1>;
					output-low;
				};
			};

			cam1@1 {
				linux,phandle = <0x59>;
				phandle = <0x59>;

				pins_cmd_dat {
					pins = <0xb00>;
					slew-rate = <0x1>;
					output-high;
				};
			};

			cam1@2 {
				linux,phandle = <0x5a>;
				phandle = <0x5a>;

				pins_cmd_dat {
					pins = <0xc00>;
					slew-rate = <0x1>;
					output-low;
				};
			};

			cam1@3 {
				linux,phandle = <0x5b>;
				phandle = <0x5b>;

				pins_cmd_dat {
					pins = <0xc00>;
					slew-rate = <0x1>;
					output-high;
				};
			};

			cam@0 {
				linux,phandle = <0x5c>;
				phandle = <0x5c>;

				pins_cmd_dat {
					pins = <0x4400>;
					slew-rate = <0x1>;
					output-low;
				};
			};

			cam@1 {
				linux,phandle = <0x5d>;
				phandle = <0x5d>;

				pins_cmd_dat {
					pins = <0x4400>;
					slew-rate = <0x1>;
					output-high;
				};
			};

			camdefault {
				linux,phandle = <0x53>;
				phandle = <0x53>;
			};

			default {
				linux,phandle = <0x2f>;
				phandle = <0x2f>;
			};

			gpslna@0 {
				linux,phandle = <0x30>;
				phandle = <0x30>;

				pins_cmd_dat {
					pins = <0x4f00>;
					slew-rate = <0x0>;
					bias-disable;
					output-low;
				};
			};

			gpslna@1 {
				linux,phandle = <0x31>;
				phandle = <0x31>;

				pins_cmd_dat {
					pins = <0x4f00>;
					slew-rate = <0x1>;
					output-high;
				};
			};

			gpslna@2 {
				linux,phandle = <0x32>;
				phandle = <0x32>;

				pins_cmd_dat {
					pins = <0x4f00>;
					slew-rate = <0x1>;
					output-low;
				};
			};

			mmc0@default {
				linux,phandle = <0x2>;
				phandle = <0x2>;

				pins_cmd {
					drive-strength = [02];
				};

				pins_dat {
					drive-strength = [02];
				};

				pins_clk {
					drive-strength = [02];
				};

				pins_rst {
					drive-strength = [02];
				};

				pins_ds {
					drive-strength = [02];
				};
			};

			mmc0@register_default {
				dat0rddly = [00];
				dat1rddly = [00];
				dat2rddly = [00];
				dat3rddly = [00];
				dat4rddly = [00];
				dat5rddly = [00];
				dat6rddly = [00];
				dat7rddly = [00];
				datwrddly = [00];
				cmdrrddly = [00];
				cmdrddly = [00];
				cmd_edge = [01];
				rdata_edge = [01];
				wdata_edge = [01];
				ett-hs200-cells = <0xc>;
				ett-hs200-default = <0xb0 0x380 0x0 0xb0 0x7c00 0x0 0xb4 0x38 0x1 0x4 0x2 0x1 0xf0 0x1f0000 0x0 0xf0 0x7c00000 0x6 0xb4 0x7 0x1 0xf0 0x1f 0xf 0x4 0x400 0x1 0xf8 0x1f000000 0x5 0xf0 0x1f00 0x12 0x4 0x4 0x0>;
				ett-hs400-cells = <0x8>;
				ett-hs400-default = <0xb0 0x380 0x0 0xb0 0x7c00 0x0 0x188 0x7c 0x2 0x188 0x1f000 0x12 0xb4 0x38 0x1 0x4 0x2 0x1 0xf0 0x1f0000 0x0 0xf0 0x7c00000 0xb>;
				linux,phandle = <0x3>;
				phandle = <0x3>;
			};

			mmc1@default {
				linux,phandle = <0x4>;
				phandle = <0x4>;

				pins_cmd {
					drive-strength = [03];
				};

				pins_dat {
					drive-strength = [03];
				};

				pins_clk {
					drive-strength = [03];
				};
			};

			mmc1@sdr104 {
				linux,phandle = <0x5>;
				phandle = <0x5>;

				pins_cmd {
					drive-strength = [02];
				};

				pins_dat {
					drive-strength = [02];
				};

				pins_clk {
					drive-strength = [03];
				};
			};

			mmc1@sdr50 {
				linux,phandle = <0x6>;
				phandle = <0x6>;

				pins_cmd {
					drive-strength = [02];
				};

				pins_dat {
					drive-strength = [02];
				};

				pins_clk {
					drive-strength = [03];
				};
			};

			mmc1@ddr50 {
				linux,phandle = <0x7>;
				phandle = <0x7>;

				pins_cmd {
					drive-strength = [02];
				};

				pins_dat {
					drive-strength = [02];
				};

				pins_clk {
					drive-strength = [03];
				};
			};

			mmc1@register_default {
				dat0rddly = [00];
				dat1rddly = [00];
				dat2rddly = [00];
				dat3rddly = [00];
				datwrddly = [00];
				cmdrrddly = [00];
				cmdrddly = [00];
				cmd_edge = [01];
				rdata_edge = [01];
				wdata_edge = [01];
				linux,phandle = <0x8>;
				phandle = <0x8>;
			};

			usb_default {
				linux,phandle = <0x47>;
				phandle = <0x47>;
			};

			iddig_irq_init {
				linux,phandle = <0x48>;
				phandle = <0x48>;

				pins_cmd_dat {
					pins = <0x1>;
					slew-rate = <0x0>;
					bias-pull-up = <0x0>;
				};
			};

			drvvbus_init {
				linux,phandle = <0x49>;
				phandle = <0x49>;

				pins_cmd_dat {
					pins = <0x6000>;
					slew-rate = <0x1>;
					bias-pull-down = <0x0>;
				};
			};

			drvvbus_low {
				linux,phandle = <0x4a>;
				phandle = <0x4a>;

				pins_cmd_dat {
					pins = <0x6000>;
					slew-rate = <0x1>;
					output-low;
					bias-pull-down = <0x0>;
				};
			};

			drvvbus_high {
				linux,phandle = <0x4b>;
				phandle = <0x4b>;

				pins_cmd_dat {
					pins = <0x6000>;
					slew-rate = <0x1>;
					output-high;
					bias-pull-down = <0x0>;
				};
			};

			hwen_high {
				linux,phandle = <0x60>;
				phandle = <0x60>;

				pins_cmd_dat {
					pins = <0x2b00>;
					slew-rate = <0x1>;
					output-high;
				};
			};

			hwen_low {
				linux,phandle = <0x61>;
				phandle = <0x61>;

				pins_cmd_dat {
					pins = <0x2b00>;
					slew-rate = <0x1>;
					output-low;
				};
			};

			audiodefault {
				linux,phandle = <0x4c>;
				phandle = <0x4c>;
			};

			audexamphigh {
				linux,phandle = <0x4d>;
				phandle = <0x4d>;

				pins_cmd_dat {
					pins = <0x400>;
					slew-rate = <0x1>;
					output-high;
				};
			};

			audexamplow {
				linux,phandle = <0x4e>;
				phandle = <0x4e>;

				pins_cmd_dat {
					pins = <0x400>;
					slew-rate = <0x1>;
					output-low;
				};
			};
		};

		i2c@11007000 {
			compatible = "mediatek,mt6735m-i2c";
			cell-index = <0x0>;
			reg = <0x11007000 0x1000>;
			interrupts = <0x0 0x54 0x8 0x0 0x63 0x8>;
			def_speed = <0x64>;
			#address-cells = <0x1>;
			#size-cells = <0x0>;

			camera_main@20 {
				compatible = "mediatek,camera_main";
				reg = <0x20>;
				status = "okay";
			};

			camera_main_af@18 {
				compatible = "mediatek,camera_main_af";
				reg = <0x18>;
				status = "okay";
			};

			camera_sub@78 {
				compatible = "mediatek,camera_sub";
				reg = <0x78>;
				status = "okay";
			};
		};

		i2c@11008000 {
			compatible = "mediatek,mt6735m-i2c";
			cell-index = <0x1>;
			reg = <0x11008000 0x1000>;
			interrupts = <0x0 0x55 0x8 0x0 0x64 0x8>;
			def_speed = <0x64>;
			#address-cells = <0x1>;
			#size-cells = <0x0>;

			cap_touch@38 {
				compatible = "mediatek,cap_touch";
				reg = <0x38>;
				status = "okay";
			};
		};

		i2c@11009000 {
			compatible = "mediatek,mt6735m-i2c";
			cell-index = <0x2>;
			reg = <0x11009000 0x1000>;
			interrupts = <0x0 0x56 0x8 0x0 0x65 0x8>;
			def_speed = <0x64>;
			#address-cells = <0x1>;
			#size-cells = <0x0>;

			gsensor@e {
				compatible = "mediatek,gsensor";
				reg = <0xe>;
				status = "okay";
			};

			alsps@49 {
				compatible = "mediatek,alsps";
				reg = <0x49>;
				status = "okay";
			};
		};

		i2c@1100f000 {
			compatible = "mediatek,mt6735m-i2c";
			cell-index = <0x3>;
			reg = <0x1100f000 0x1000>;
			interrupts = <0x0 0x57 0x8 0x0 0x66 0x8>;
			def_speed = <0x64>;
			#address-cells = <0x1>;
			#size-cells = <0x0>;
		};

		SPI1@0x1100A000 {
			cell-index = <0x0>;
			spi-padmacro = <0x0>;
			compatible = "mediatek,SPI1";
			reg = <0x1100a000 0x1000>;
			interrupts = <0x0 0x76 0x8>;
		};

		touch@ {
			compatible = "mediatek,mt6735-touch", "mediatek,mt6735m-touch";
			vtouch-supply = <0x3e>;
			interrupt-parent = <0xa>;
			interrupts = <0xa 0x2>;
			debounce = <0xa 0x0>;
			status = "okay";
			tpd-resolution = <0x2d0 0x500>;
			use-tpd-button = <0x1>;
			tpd-key-num = <0x4>;
			tpd-key-local = <0x8b 0x9e 0xd9 0xac 0x0>;
			tpd-key-dim-local = <0xa0 0x7d0 0x46 0x28 0x3b6 0x7d0 0x46 0x28 0xc8 0x7d0 0x46 0x28 0x21c 0x7d0 0x46 0x28 0x0 0x0 0x0 0x0>;
			tpd-max-touch-num = <0x2>;
			tpd-filter-enable = <0x1>;
			tpd-filter-pixel-density = <0x5d>;
			tpd-filter-custom-prameters = <0x0 0x0 0x0 0x0 0x0 0x0 0x0 0x0 0x0 0x0 0x0 0x0>;
			tpd-filter-custom-speed = <0xf 0xf 0x0>;
			pinctrl-names = "default", "state_eint_as_int", "state_eint_output0", "state_eint_output1", "state_rst_output0", "state_rst_output1";
			pinctrl-0 = <0x3f>;
			pinctrl-1 = <0x40>;
			pinctrl-2 = <0x41>;
			pinctrl-3 = <0x42>;
			pinctrl-4 = <0x43>;
			pinctrl-5 = <0x44>;
		};

		accdet@ {
			compatible = "mediatek,mt6735-accdet", "mediatek,mt6735m-accdet";
			interrupt-parent = <0xa>;
			interrupts = <0x6 0x8>;
			debounce = <0x6 0x3e800>;
			status = "okay";
			accdet-mic-vol = <0x7>;
			headset-mode-setting = <0x500 0x200 0x1 0x1f0 0x800 0x800 0x20>;
			accdet-plugout-debounce = <0x14>;
			accdet-mic-mode = <0x1>;
			headset-three-key-threshold = <0x0 0x50 0xdc 0x1f4>;
			headset-four-key-threshold = <0x0 0x3a 0x79 0xc0 0x1c2>;
			pinctrl-names = "default", "state_eint_as_int";
			pinctrl-0 = <0x45>;
			pinctrl-1 = <0x46>;
		};

		THERM_CTRL@0x1100B000 {
			compatible = "mediatek,THERM_CTRL";
			reg = <0x1100b000 0x1000>;
			interrupts = <0x0 0x4e 0x8>;
		};

		ptp_fsm@1100b000 {
			compatible = "mediatek,ptp_fsm_v1";
			reg = <0x1100b000 0x1000>;
			interrupts = <0x0 0x7d 0x8>;
		};

		AP_DMA_BTIF_TX@0x11000780 {
			compatible = "mediatek,AP_DMA_BTIF_TX";
			reg = <0x11000780 0x80>;
			interrupts = <0x0 0x6f 0x8>;
		};

		AP_DMA_BTIF_RX@0x11000800 {
			compatible = "mediatek,AP_DMA_BTIF_RX";
			reg = <0x11000800 0x80>;
			interrupts = <0x0 0x70 0x8>;
		};

		BTIF@0x1100C000 {
			compatible = "mediatek,BTIF";
			reg = <0x1100c000 0x1000>;
			interrupts = <0x0 0x5a 0x8>;
		};

		nfc@0 {
			compatible = "mediatek,nfc-gpio-v2";
			gpio-ven = <0x4>;
			gpio-rst = <0x3>;
			gpio-eint = <0x1>;
			gpio-irq = <0x2>;
		};

		gps {
			compatible = "mediatek,mt3326-gps";
		};

		btcvsd@10000000 {
			compatible = "mediatek,audio_bt_cvsd";
			offset = <0x700 0x800 0xfd0 0xfd4 0xfd8>;
			reg = <0x10000000 0x1000 0x18000000 0x10000 0x18080000 0x8000>;
			interrupts = <0x0 0xe4 0x8>;
		};

		wifi@180F0000 {
			compatible = "mediatek,wifi";
			reg = <0x180f0000 0x5c>;
			interrupts = <0x0 0xe2 0x8>;
		};

		NFI@0x1100D000 {
			compatible = "mediatek,NFI";
			reg = <0x1100d000 0x1000>;
			interrupts = <0x0 0x60 0x8>;
		};

		DISP_PWM0@0x1100E000 {
			compatible = "mediatek,DISP_PWM0";
			reg = <0x1100e000 0x1000>;
		};

		IRDA@0x11010000 {
			compatible = "mediatek,IRDA";
			reg = <0x11010000 0x1000>;
		};

		usb20@11200000 {
			compatible = "mediatek,mt6735-usb20";
			cell-index = <0x0>;
			reg = <0x11200000 0x10000 0x11210000 0x10000>;
			interrupts = <0x0 0x48 0x8>;
			mode = <0x2>;
			multipoint = <0x1>;
			dyn_fifo = <0x1>;
			soft_con = <0x1>;
			dma = <0x1>;
			num_eps = <0x10>;
			dma_channels = <0x8>;
			drvvbus_gpio = <0x60 0x2>;
			iddig_gpio = <0x0 0x1>;
			pinctrl-names = "usb_default", "iddig_irq_init", "drvvbus_init", "drvvbus_low", "drvvbus_high";
			pinctrl-0 = <0x47>;
			pinctrl-1 = <0x48>;
			pinctrl-2 = <0x49>;
			pinctrl-3 = <0x4a>;
			pinctrl-4 = <0x4b>;
			status = "okay";
		};

		audio@11220000 {
			compatible = "mediatek,audio";
			reg = <0x11220000 0x10000>;
			interrupts = <0x0 0x90 0x8>;
		};

		mt_soc_dl1_pcm@11220000 {
			compatible = "mediatek,mt-soc-dl1-pcm";
			reg = <0x11220000 0x1000>;
			interrupts = <0x0 0x90 0x8>;
			audclk-gpio = <0x8f 0x0>;
			audmiso-gpio = <0x90 0x0>;
			audmosi-gpio = <0x91 0x0>;
			vowclk-gpio = <0x94 0x0>;
			extspkamp-gpio = <0x4 0x0>;
			i2s1clk-gpio = <0x50 0x0>;
			i2s1dat-gpio = <0x4e 0x0>;
			i2s1mclk-gpio = <0x9 0x0>;
			i2s1ws-gpio = <0x4f 0x0>;
			pinctrl-names = "default", "extamp-pullhigh", "extamp-pulllow";
			pinctrl-0 = <0x4c>;
			pinctrl-1 = <0x4d>;
			pinctrl-2 = <0x4e>;
			status = "okay";
		};

		mt_soc_ul1_pcm@11220000 {
			compatible = "mediatek,mt_soc_pcm_capture";
		};

		mt_soc_voice_md1@11220000 {
			compatible = "mediatek,mt_soc_pcm_voice_md1";
		};

		mt_soc_hdmi_pcm@11220000 {
			compatible = "mediatek,mt_soc_pcm_hdmi";
		};

		mt_soc_uldlloopback_pcm@11220000 {
			compatible = "mediatek,mt_soc_pcm_uldlloopback";
		};

		mt_soc_i2s0_pcm@11220000 {
			compatible = "mediatek,mt_soc_pcm_dl1_i2s0";
		};

		mt_soc_mrgrx_pcm@11220000 {
			compatible = "mediatek,mt_soc_pcm_mrgrx";
		};

		mt_soc_mrgrx_awb_pcm@11220000 {
			compatible = "mediatek,mt_soc_pcm_mrgrx_awb";
		};

		mt_soc_fm_i2s_pcm@11220000 {
			compatible = "mediatek,mt_soc_pcm_fm_i2s";
		};

		mt_soc_fm_i2s_awb_pcm@11220000 {
			compatible = "mediatek,mt_soc_pcm_fm_i2s_awb";
		};

		mt_soc_i2s0dl1_pcm@11220000 {
			compatible = "mediatek,mt_soc_pcm_dl1_i2s0Dl1";
		};

		mt_soc_dl1_awb_pcm@11220000 {
			compatible = "mediatek,mt_soc_pcm_dl1_awb";
		};

		mt_soc_voice_md1_bt@11220000 {
			compatible = "mediatek,mt_soc_pcm_voice_md1_bt";
		};

		mt_soc_voip_bt_out@11220000 {
			compatible = "mediatek,mt_soc_pcm_dl1_bt";
		};

		mt_soc_voip_bt_in@11220000 {
			compatible = "mediatek,mt_soc_pcm_bt_dai";
		};

		mt_soc_tdmrx_pcm@11220000 {
			compatible = "mediatek,mt_soc_tdm_capture";
		};

		mt_soc_fm_mrgtx_pcm@11220000 {
			compatible = "mediatek,mt_soc_pcm_fmtx";
		};

		mt_soc_ul2_pcm@11220000 {
			compatible = "mediatek,mt_soc_pcm_capture2";
		};

		mt_soc_i2s0_awb_pcm@11220000 {
			compatible = "mediatek,mt_soc_pcm_i2s0_awb";
		};

		mt_soc_voice_md2@11220000 {
			compatible = "mediatek,mt_soc_pcm_voice_md2";
		};

		mt_soc_routing_pcm@11220000 {
			compatible = "mediatek,mt_soc_pcm_routing";
			i2s1clk-gpio = <0x7 0x6>;
			i2s1dat-gpio = <0x5 0x6>;
			i2s1mclk-gpio = <0x9 0x6>;
			i2s1ws-gpio = <0x6 0x6>;
		};

		mt_soc_voice_md2_bt@11220000 {
			compatible = "mediatek,mt_soc_pcm_voice_md2_bt";
		};

		mt_soc_hp_impedance_pcm@11220000 {
			compatible = "mediatek,Mt_soc_pcm_hp_impedance";
		};

		mt_soc_codec_name@11220000 {
			compatible = "mediatek,mt_soc_codec_63xx";
		};

		mt_soc_dummy_pcm@11220000 {
			compatible = "mediatek,mt_soc_pcm_dummy";
		};

		mt_soc_codec_dummy_name@11220000 {
			compatible = "mediatek,mt_soc_codec_dummy";
		};

		mt_soc_routing_dai_name@11220000 {
			compatible = "mediatek,mt_soc_dai_routing";
		};

		mt_soc_dai_name@11220000 {
			compatible = "mediatek,mt_soc_dai_stub";
		};

		mt_soc_offload_gdma@11220000 {
			compatible = "mediatek,mt_soc_pcm_offload_gdma";
		};

		mt_soc_dl2_pcm@11220000 {
			compatible = "mediatek,mt_soc_pcm_dl2";
		};

		USB1@0x11260000 {
			compatible = "mediatek,USB1";
			reg = <0x11260000 0x10000>;
			interrupts = <0x0 0x49 0x8>;
		};

		MSDC3@0x11260000 {
			compatible = "mediatek,MSDC3";
			reg = <0x11260000 0x10000>;
		};

		WCN_AHB@0x11270000 {
			compatible = "mediatek,WCN_AHB";
			reg = <0x11270000 0x10000>;
			interrupts = <0x0 0xe4 0x8>;
		};

		MDPERIPHERALS@0x20000000 {
			compatible = "mediatek,MD PERIPHERALS";
			reg = <0x20000000 0x0>;
		};

		MD2PERIPHERALS@0x30000000 {
			compatible = "mediatek,MD2 PERIPHERALS";
			reg = <0x30000000 0x0>;
		};

		C2KPERIPHERALS@0x38000000 {
			compatible = "mediatek,C2K PERIPHERALS";
			reg = <0x38000000 0x0>;
		};

		MFGCFG@0x13000000 {
			compatible = "mediatek,MFGCFG";
			reg = <0x13000000 0x1000>;
			interrupts = <0x0 0xd2 0x8>;
		};

		MALI@0x13040000 {
			compatible = "arm,malit720", "arm,mali-t72x", "arm,malit7xx", "arm,mali-midgard";
			reg = <0x13040000 0x4000>;
			interrupts = <0x0 0xd4 0x8 0x0 0xd3 0x8 0x0 0xd2 0x8>;
			interrupt-names = "JOB", "MMU", "GPU";
			clock-frequency = <0x1ad27480>;
		};

		mmsys_config@14000000 {
			compatible = "mediatek,mmsys_config";
			reg = <0x14000000 0x1000>;
			interrupts = <0x0 0xce 0x8>;
		};

		mdp_rdma@14001000 {
			compatible = "mediatek,mdp_rdma";
			reg = <0x14001000 0x1000>;
			interrupts = <0x0 0xbb 0x8>;
		};

		mdp_rsz0@14002000 {
			compatible = "mediatek,mdp_rsz0";
			reg = <0x14002000 0x1000>;
			interrupts = <0x0 0xbc 0x8>;
		};

		mdp_rsz1@14003000 {
			compatible = "mediatek,mdp_rsz1";
			reg = <0x14003000 0x1000>;
			interrupts = <0x0 0xbd 0x8>;
		};

		mdp_wdma@14004000 {
			compatible = "mediatek,mdp_wdma";
			reg = <0x14004000 0x1000>;
			interrupts = <0x0 0xbf 0x8>;
		};

		mdp_wrot@14005000 {
			compatible = "mediatek,mdp_wrot";
			reg = <0x14005000 0x1000>;
			interrupts = <0x0 0xc0 0x8>;
		};

		mdp_tdshp@14006000 {
			compatible = "mediatek,mdp_tdshp";
			reg = <0x14006000 0x1000>;
			interrupts = <0x0 0xbe 0x8>;
		};

		DISPSYS@0x14007000 {
			compatible = "mediatek,DISPSYS";
			reg = <0x14007000 0x1000 0x0 0x0 0x14009000 0x1000 0x0 0x0 0x1400b000 0x1000 0x1400c000 0x1000 0x1400d000 0x1000 0x1400e000 0x1000 0x1400f000 0x1000 0x14010000 0x1000 0x0 0x0 0x1100e000 0x1000 0x0 0x0 0x14015000 0x1000 0x14012000 0x1000 0x14013000 0x1000 0x14000000 0x1000 0x14016000 0x1000 0x14017000 0x1000 0x14018000 0x1000 0x10206000 0x1000 0x10210000 0x1000 0x10211a70 0xc 0x10211974 0xc 0x10211b70 0xc 0x10206044 0xc 0x10206514 0xc 0x10206558 0xc 0x102100a0 0x1000 0x10209260 0x1000 0x10209264 0x1000 0x0 0x0 0x10209000 0x1000>;
			interrupts = <0x0 0xc1 0x8 0x0 0x0 0x8 0x0 0xc3 0x8 0x0 0x0 0x8 0x0 0xc5 0x8 0x0 0xc6 0x8 0x0 0xc7 0x8 0x0 0xc8 0x8 0x0 0xc9 0x8 0x0 0xca 0x8 0x0 0x0 0x8 0x0 0x75 0x8 0x0 0x0 0x8 0x0 0xba 0x8 0x0 0xcc 0x8 0x0 0xcd 0x8 0x0 0xce 0x8 0x0 0xb0 0x8 0x0 0x0 0x8 0x0 0x0 0x8 0x0 0x0 0x8 0x0 0x0 0x8 0x0 0x0 0x8 0x0 0x0 0x8 0x0 0x0 0x8 0x0 0x0 0x8 0x0 0x0 0x8 0x0 0x0 0x8>;
		};

		DISP_OVL0@0x14007000 {
			compatible = "mediatek,DISP_OVL0";
			reg = <0x14007000 0x1000>;
			interrupts = <0x0 0xc1 0x8>;
		};

		DISP_OVL1@0x14008000 {
			compatible = "mediatek,DISP_OVL1";
			reg = <0x14008000 0x1000>;
			interrupts = <0x0 0xc2 0x8>;
		};

		DISP_RDMA0@0x14009000 {
			compatible = "mediatek,DISP_RDMA0";
			reg = <0x14009000 0x1000>;
			interrupts = <0x0 0xc3 0x8>;
		};

		DISP_RDMA1@0x1400A000 {
			compatible = "mediatek,DISP_RDMA1";
			reg = <0x1400a000 0x1000>;
			interrupts = <0x0 0xc4 0x8>;
		};

		gpio@0x10000e00 {
			compatible = "mediatek,fpga_gpio";
			reg = <0x10000e00 0x100>;
		};

		DISP_WDMA0@0x1400B000 {
			compatible = "mediatek,DISP_WDMA0";
			reg = <0x1400b000 0x1000>;
			interrupts = <0x0 0xc5 0x8>;
		};

		DISP_COLOR@0x1400C000 {
			compatible = "mediatek,DISP_COLOR";
			reg = <0x1400c000 0x1000>;
			interrupts = <0x0 0xc6 0x8>;
		};

		DISP_CCORR@0x1400D000 {
			compatible = "mediatek,DISP_CCORR";
			reg = <0x1400d000 0x1000>;
			interrupts = <0x0 0xc7 0x8>;
		};

		DISP_AAL@0x1400E000 {
			compatible = "mediatek,DISP_AAL";
			reg = <0x1400e000 0x1000>;
			interrupts = <0x0 0xc8 0x8>;
		};

		DISP_GAMMA@0x1400F000 {
			compatible = "mediatek,DISP_GAMMA";
			reg = <0x1400f000 0x1000>;
			interrupts = <0x0 0xc9 0x8>;
		};

		DISP_DITHER@0x14010000 {
			compatible = "mediatek,DISP_DITHER";
			reg = <0x14010000 0x1000>;
			interrupts = <0x0 0xca 0x8>;
		};

		DISP_UFOE@0x14011000 {
			compatible = "mediatek,DISP_UFOE";
			reg = <0x14011000 0x1000>;
			interrupts = <0x0 0xcb 0x8>;
		};

		DSI0@0x14012000 {
			compatible = "mediatek,DSI0";
			reg = <0x14012000 0x1000>;
			interrupts = <0x0 0xcc 0x8>;
		};

		DPI0@0x14013000 {
			compatible = "mediatek,DPI0";
			reg = <0x14013000 0x1000>;
			interrupts = <0x0 0xcd 0x8>;
		};

		DISP_PWM@0x14014000 {
			compatible = "mediatek,DISP_PWM";
			reg = <0x14014000 0x1000>;
		};

		MM_MUTEX@0x14015000 {
			compatible = "mediatek,MM_MUTEX";
			reg = <0x14015000 0x1000>;
			interrupts = <0x0 0xba 0x8>;
		};

		met_smi@14017000 {
			compatible = "mediatek,met_smi";
			reg = <0x14017000 0x1000 0x14016000 0x1000 0x16010000 0x1000 0x15001000 0x1000 0x17001000 0x1000>;
		};

		MIPI_TX_CONFIG@0x14018000 {
			compatible = "mediatek,MIPI_TX_CONFIG";
			reg = <0x14018000 0x1000>;
		};

		ISPSYS@0x15000000 {
			compatible = "mediatek,ISPSYS";
			reg = <0x15004000 0x9000 0x15000000 0x10000 0x10215000 0x1000>;
			interrupts = <0x0 0xb6 0x8 0x0 0xb7 0x8>;
		};

		kd_camera_hw1@15008000 {
			compatible = "mediatek,camera_hw";
			reg = <0x15008000 0x1000>;
			vcama-supply = <0x4f>;
			vcamd-supply = <0x50>;
			vcamaf-supply = <0x51>;
			vcamio-supply = <0x52>;
			vcama_main2-supply = <0x4f>;
			vcama_sub-supply = <0x4f>;
			vcamaf_main2-supply = <0x51>;
			vcamaf_sub-supply = <0x51>;
			vcamd_main2-supply = <0x50>;
			vcamd_sub-supply = <0x50>;
			vcamio_main2-supply = <0x52>;
			vcamio_sub-supply = <0x52>;
			status = "okay";
			pinctrl-names = "default", "cam0_rst0", "cam0_rst1", "cam0_pnd0", "cam0_pnd1", "cam1_rst0", "cam1_rst1", "cam1_pnd0", "cam1_pnd1", "cam_ldo0_0", "cam_ldo0_1";
			pinctrl-0 = <0x53>;
			pinctrl-1 = <0x54>;
			pinctrl-2 = <0x55>;
			pinctrl-3 = <0x56>;
			pinctrl-4 = <0x57>;
			pinctrl-5 = <0x58>;
			pinctrl-6 = <0x59>;
			pinctrl-7 = <0x5a>;
			pinctrl-8 = <0x5b>;
			pinctrl-9 = <0x5c>;
			pinctrl-10 = <0x5d>;
		};

		kd_camera_hw2@15008000 {
			compatible = "mediatek,camera_hw2";
			reg = <0x15008000 0x1000>;
		};

		ISP_SYSR@0x15000000 {
			compatible = "mediatek,ISP_SYSR";
		};

		ISP_PIPEM@0x15000000 {
			compatible = "mediatek,ISP_PIPEM";
		};

		SENINF_TOP@0x15008000 {
			compatible = "mediatek,SENINF_TOP";
			reg = <0x15008000 0x1000>;
			interrupts = <0x0 0xb6 0x8>;
		};

		CAM@0x15004000 {
			compatible = "mediatek,CAM";
			reg = <0x15004000 0x1000>;
			interrupts = <0x0 0xb7 0x8>;
		};

		VENC@0x15009000 {
			compatible = "mediatek,VENC";
			reg = <0x15009000 0x1000>;
			interrupts = <0x0 0xb4 0x8>;
		};

		VDEC@0x1500B000 {
			compatible = "mediatek,VDEC";
			reg = <0x1500b000 0x1000>;
		};

		JPGENC@0x1500A000 {
			compatible = "mediatek,JPGENC";
			reg = <0x1500a000 0x1000>;
			interrupts = <0x0 0xb5 0x8>;
		};

		VDEC_GCON@0x16000000 {
			compatible = "mediatek,VDEC_GCON";
			reg = <0x16000000 0x1000>;
		};

		VDEC_FULL_TOP@0x16020000 {
			compatible = "mediatek,VDEC_FULL_TOP";
			reg = <0x16020000 0x10000>;
			interrupts = <0x0 0xb3 0x8>;
		};

		CHIPID@08000000 {
			compatible = "mediatek,CHIPID";
			reg = <0x8000000 0x4 0x8000004 0x4 0x8000008 0x4 0x800000c 0x4>;
		};

		pwm@11006000 {
			compatible = "mediatek,pwm";
			reg = <0x11006000 0x1000>;
			interrupts = <0x0 0x4d 0x8>;
		};

		MTKFB@5e200000 {
			compatible = "mediatek,MTKFB";
			reg = <0x7f000000 0x1000000>;
		};
	};

	lcm {
		compatible = "mediatek,lcm";
	};

	hwmsensor@0 {
		compatible = "mediatek,hwmsensor";
	};

	gsensor@0 {
		compatible = "mediatek,gsensor";
	};

	als_ps@0 {
		compatible = "mediatek,als_ps";
		pinctrl-names = "pin_default", "pin_cfg";
		pinctrl-0 = <0x5e>;
		pinctrl-1 = <0x5f>;
		status = "okay";
	};

	m_acc_pl@0 {
		compatible = "mediatek,m_acc_pl";
	};

	m_alsps_pl@0 {
		compatible = "mediatek,m_alsps_pl";
	};

	m_batch_pl@0 {
		compatible = "mediatek,m_batch_pl";
	};

	batchsensor@0 {
		compatible = "mediatek,batchsensor";
	};

	gyroscope@0 {
		compatible = "mediatek,gyroscope";
	};

	m_gyro_pl@0 {
		compatible = "mediatek,m_gyro_pl";
	};

	barometer@0 {
		compatible = "mediatek,barometer";
	};

	m_baro_pl@0 {
		compatible = "mediatek,m_baro_pl";
	};

	msensor@0 {
		compatible = "mediatek,msensor";
	};

	m_mag_pl@0 {
		compatible = "mediatek,m_mag_pl";
	};

	orientation@0 {
		compatible = "mediatek,orientation";
	};

	MOBICORE {
		compatible = "trustonic,mobicore";
		interrupts = <0x0 0xf8 0x1>;
	};

	rf_clock_buffer {
		compatible = "mediatek,rf_clock_buffer";
		mediatek,clkbuf-quantity = <0x4>;
		mediatek,clkbuf-config = <0x2 0x1 0x1 0x1>;
		status = "okay";
	};

	trusty {
		compatible = "android,trusty-smc-v1";
		ranges;
		#address-cells = <0x2>;
		#size-cells = <0x2>;

		irq {
			compatible = "android,trusty-irq-v1";
		};

		log {
			compatible = "android,trusty-log-v1";
		};

		virtio {
			compatible = "android,trusty-virtio-v1";
		};
	};

	flashlight {
		compatible = "mediatek,mt6735-flashlight";
		pinctrl-names = "default", "hwen_high", "hwen_low";
		pinctrl-0 = <0x2f>;
		pinctrl-1 = <0x60>;
		pinctrl-2 = <0x61>;
		status = "okay";
	};

	led@6 {
		compatible = "mediatek,lcd-backlight";
		led_mode = <0x5>;
		data = <0x0>;
		pwm_config = <0x0 0x0 0x0 0x0 0x0>;
	};

	vibrator@0 {
		compatible = "mediatek,vibrator";
		vib_timer = <0x19>;
		vib_limit = <0x9>;
		vib_vol = <0x5>;
	};

	cust_accel@0 {
		compatible = "mediatek,kxtj2_1009_new";
		i2c_num = <0x2>;
		i2c_addr = <0xe 0x0 0x0 0x0>;
		direction = <0x5>;
		power_id = <0xffff>;
		power_vol = <0x0>;
		firlen = <0x0>;
		is_batch_supported = <0x0>;
	};

	cust_alsps@0 {
		compatible = "mediatek,epl2182";
		i2c_num = <0x2>;
		i2c_addr = <0x49 0x0 0x0 0x0>;
		polling_mode_ps = <0x0>;
		polling_mode_als = <0x1>;
		power_id = <0xffff>;
		power_vol = <0x0>;
		als_level = <0xf 0x14 0x23 0x37 0x4b 0x5a 0x64 0x3e8 0x7d0 0xbb8 0x1770 0x2710 0x36b0 0x4650 0x4e20>;
		als_value = <0x14 0x28 0x5a 0x64 0xa0 0xb4 0xe1 0x140 0x280 0x500 0x500 0xa28 0xa28 0xa28 0x2800 0x2800>;
		ps_threshold_high = <0x12c>;
		ps_threshold_low = <0x96>;
		is_batch_supported_ps = <0x0>;
		is_batch_supported_als = <0x0>;
	};
};
